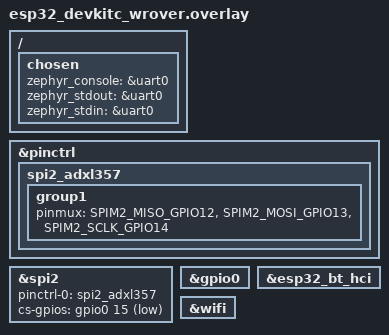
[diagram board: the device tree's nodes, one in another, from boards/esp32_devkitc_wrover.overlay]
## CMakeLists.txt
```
cmake_minimum_required(VERSION 3.20.0)
# Top-level CMakeLists.txt for the skeleton application.
#
# Copyright (c) 2017 Open Source Foundries Limited
#
# SPDX-License-Identifier: Apache-2.0
#
# This provides a basic application structure suitable for communication using
# mcumgr.  It can be used as a starting point for new applications.

# Standard Zephyr application boilerplate.
find_package(Zephyr REQUIRED HINTS $ENV{ZEPHYR_BASE})
project(smp)

target_sources(app PRIVATE src/main.c)
target_sources_ifdef(CONFIG_GPIO app PRIVATE src/sensor.c)
target_sources_ifdef(CONFIG_MCUMGR_TRANSPORT_UDP app PRIVATE src/wifi.c)
target_sources_ifdef(CONFIG_MCUMGR_TRANSPORT_BT app PRIVATE src/bluetooth.c)
target_sources_ifdef(CONFIG_SHELL app PRIVATE src/shell.c)
```

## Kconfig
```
mainmenu "Zephyr"
source "Kconfig.zephyr"
menu "Shell Configuration"
config MCUMGR_CMD_SHELL_MGMT
    bool "Enable mcumgr handlers for shell management"
    select SHELL_BACKEND_DUMMY
    depends on SHELL && MCUMGR
    help
      Enables mcumgr handlers for shell management. The handler will utilize
      the dummy backend to execute shell commands and capture the output to
      an internal memory buffer. This way, there is no interaction with
      physical interfaces outside of the scope of the user.
      It is possible to use additional shell backends in coordination
      with this handler and they will not interfere.

endmenu
```

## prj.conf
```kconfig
# Enable MCUmgr and dependencies.
CONFIG_NET_BUF=y
CONFIG_ZCBOR=y
CONFIG_CRC=y
CONFIG_MCUMGR=y
CONFIG_STREAM_FLASH=y
CONFIG_FLASH_MAP=y
CONFIG_BOOT_BANNER=y
CONFIG_STDOUT_CONSOLE=y

# Some command handlers require a large stack.
CONFIG_ESPTOOLPY_FLASHSIZE_8MB=y
CONFIG_MAIN_STACK_SIZE=8192
CONFIG_SYSTEM_WORKQUEUE_STACK_SIZE=8192

# Ensure an MCUboot-compatible binary is generated.
# ./esptool.py --chip esp32 --port /dev/ttyUSB0 write_flash 0x1000 build/bootloader/zephyr/zephyr.bin for use mcuboot
CONFIG_BOOTLOADER_MCUBOOT=n

# Enable flash operations.
CONFIG_FLASH=y

# Enable statistics and statistic names.
CONFIG_STATS=y
CONFIG_STATS_NAMES=y

# For debugging purposes.
# CONFIG_THREAD_ANALYZER=y
# CONFIG_THREAD_NAME=y /bu
# CONFIG_ASSERT=y
# CONFIG_STACK_SENTINEL=y /bu
# CONFIG_DEBUG_OPTIMIZATIONS=y

# Enable most core commands.
# CONFIG_BOOTLOADER_MCUBOOT
CONFIG_IMG_MANAGER=n
CONFIG_MCUMGR_GRP_IMG=n
CONFIG_MCUMGR_GRP_OS=y
CONFIG_MCUMGR_GRP_STAT=y

# Required by the `taskstat` command.
CONFIG_THREAD_MONITOR=y

# Enable OS management for echo and taskstat commands.
CONFIG_MCUMGR_GRP_OS_ECHO=y
CONFIG_MCUMGR_GRP_OS_TASKSTAT=y

# Enable logging
CONFIG_LOG=n
CONFIG_MCUBOOT_UTIL_LOG_LEVEL_WRN=n
# Disable debug logging
# CONFIG_LOG_MAX_LEVEL=3

# For writing
CONFIG_CONSOLE=y
CONFIG_UART_CONSOLE=y
CONFIG_PRINTK=y
```

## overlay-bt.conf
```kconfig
CONFIG_BT=y
CONFIG_BT_HCI=y
CONFIG_BT_DEVICE_NAME="ESP32 Zephyr SMP"
CONFIG_BT_PERIPHERAL=y

# Allow for large Bluetooth data packets.
CONFIG_BT_L2CAP_TX_MTU=512
CONFIG_BT_BUF_ACL_RX_SIZE=512
CONFIG_BT_BUF_ACL_TX_SIZE=512
CONFIG_SHELL_CMD_BUFF_SIZE=256
CONFIG_MCUMGR_TRANSPORT_NETBUF_SIZE=1024

CONFIG_BT_GATT_DYNAMIC_DB=y
# Enable the long workqueue for Bluetooth.
CONFIG_BT_LONG_WQ=y

# Disable pairing/encryption
CONFIG_BT_PRIVACY=n
# CONFIG_BT_SMP=n
CONFIG_BT_BONDABLE=n

# MCUMGR shell transport.
CONFIG_BASE64=y
CONFIG_SHELL=y
CONFIG_CRC=y
CONFIG_SHELL_BACKEND_SERIAL=y
CONFIG_SHELL_BACKEND_DUMMY=y
CONFIG_MCUMGR_GRP_SHELL=y
CONFIG_MCUMGR_TRANSPORT_SHELL=n

# Enable the LittleFS file system.
CONFIG_FILE_SYSTEM=y
CONFIG_FILE_SYSTEM_LITTLEFS=y

# Enable file system commands
CONFIG_MCUMGR_GRP_FS=y

# Enable the Bluetooth mcumgr transport (unauthenticated).
CONFIG_MCUMGR_TRANSPORT_BT=y
CONFIG_MCUMGR_LOG_LEVEL_DBG=y
CONFIG_MCUMGR_TRANSPORT_BT_CONN_PARAM_CONTROL=y

# Config size for Bluetooth stacks and workqueues.
CONFIG_SHELL_BACKEND_DUMMY_BUF_SIZE=2048
CONFIG_BT_RX_STACK_SIZE=4096
CONFIG_MCUMGR_TRANSPORT_WORKQUEUE_STACK_SIZE=4096
CONFIG_SHELL_STACK_SIZE=4096

# If you want to change BT_HCI_TX_STACK_SIZE you should do it from the menuconfig.
# CONFIG_BT_HCI_TX_STACK_SIZE=4096
# CONFIG_BT_LONG_WQ_STACK_SIZE=4096
# CONFIG_BT_HCI_TX_STACK_SIZE=4096
```

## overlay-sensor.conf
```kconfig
CONFIG_SPI=y
CONFIG_GPIO=y
CONFIG_PINCTRL=y
CONFIG_SPI_EXTENDED_MODES=y
CONFIG_NEWLIB_LIBC=n
CONFIG_MINIMAL_LIBC=y
CONFIG_COMMON_LIBC_MALLOC_ARENA_SIZE=4096
CONFIG_STDOUT_CONSOLE=n
CONFIG_CBPRINTF_FP_SUPPORT=y
CONFIG_SHELL_LOG_BACKEND=y
CONFIG_LOG_MODE_IMMEDIATE=y
```

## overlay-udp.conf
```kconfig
# MCUmgr UDP
CONFIG_MCUMGR_TRANSPORT_UDP=y
CONFIG_MCUMGR_TRANSPORT_UDP_IPV4=y
CONFIG_MCUMGR_TRANSPORT_UDP_PORT=1337

# MCUMGR shell transport.
CONFIG_BASE64=y
CONFIG_SHELL=y
CONFIG_CRC=y
CONFIG_SHELL_BACKEND_SERIAL=y
CONFIG_SHELL_BACKEND_DUMMY=y
CONFIG_MCUMGR_GRP_SHELL=y
CONFIG_MCUMGR_TRANSPORT_SHELL=n


# Debug logs to catch socket()/bind() failures
CONFIG_LOG=n
CONFIG_NET_LOG=n
CONFIG_THREAD_ANALYZER=n
CONFIG_WIFI_LOG_LEVEL_INF=n
CONFIG_LOG_BACKEND_UART=n
CONFIG_LOG_MODE_IMMEDIATE=n
# CONFIG_WIFI_LOG_LEVEL_DBG=y

# Networking core
CONFIG_NETWORKING=y
CONFIG_NET_SHELL=y
CONFIG_NET_IPV4=y
CONFIG_NET_MGMT=y
CONFIG_NET_UDP=y
CONFIG_NET_SOCKETS=y
CONFIG_NET_CONNECTION_MANAGER=y
CONFIG_NET_CONFIG_SETTINGS=y
CONFIG_NET_CONFIG_AUTO_INIT=n
CONFIG_NET_DHCPV4=y


# ESP32 Wi‑Fi driver + required L2 shim
CONFIG_NEWLIB_LIBC=y
CONFIG_WIFI=y
CONFIG_WIFI_ESP32=y
CONFIG_NET_L2_WIFI_MGMT=y
CONFIG_NET_L2_WIFI_SHELL=y
CONFIG_NET_L2_ETHERNET=y

CONFIG_NET_MGMT_EVENT=y
CONFIG_NET_MGMT_EVENT_INFO=y

# Shell capture buffers (optional but helpful)
CONFIG_SHELL_BACKEND_DUMMY_BUF_SIZE=2048
CONFIG_MCUMGR_TRANSPORT_NETBUF_SIZE=2048


CONFIG_NET_PKT_RX_COUNT=10
CONFIG_NET_PKT_TX_COUNT=10

CONFIG_NET_BUF_RX_COUNT=20
CONFIG_NET_BUF_TX_COUNT=20

CONFIG_NET_MAX_CONTEXTS=10

CONFIG_POSIX_MAX_FDS=32
CONFIG_NET_SOCKETS_POLL_MAX=8

# Safer stacks for net paths
CONFIG_NET_RX_STACK_SIZE=12288
CONFIG_NET_TX_STACK_SIZE=8192
CONFIG_MCUMGR_TRANSPORT_UDP_STACK_SIZE=8192
CONFIG_MCUMGR_TRANSPORT_WORKQUEUE_STACK_SIZE=8192

# Remove until working
# CONFIG_TEST_RANDOM_GENERATOR=y
# CONFIG_NET_CONFIG_MY_IPV4_ADDR="192.168.88.244"
```

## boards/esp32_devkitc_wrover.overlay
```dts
#include <zephyr/dt-bindings/pinctrl/esp32-pinctrl.h>

/ {
    chosen {
        zephyr_console = &uart0;
        zephyr_stdout  = &uart0;
        zephyr_stdin   = &uart0;
    };
};

&pinctrl {
    spi2_adxl357: spi2_adxl357 {
        group1 {
            pinmux = <SPIM2_MISO_GPIO12>,    // MISO → GPIO12
                     <SPIM2_MOSI_GPIO13>,    // MOSI → GPIO13
                     <SPIM2_SCLK_GPIO14>;    // SCLK → GPIO14
        };
    };
};

&spi2 {
    status = "okay";
    pinctrl-0 = <&spi2_adxl357>;
    pinctrl-names = "default";
    cs-gpios = <&gpio0 15 GPIO_ACTIVE_LOW>;
};

&gpio0 {
    status = "okay";
};

&esp32_bt_hci {
    status = "okay";
};

&wifi {
	status = "okay";
};
```

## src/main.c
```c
#include <zephyr/kernel.h>
#include <zephyr/stats/stats.h>
#include <zephyr/usb/usb_device.h>
#include <zephyr/debug/thread_analyzer.h>

#ifdef CONFIG_MCUMGR_GRP_FS
#include <zephyr/device.h>
#include <zephyr/fs/fs.h>
#include <zephyr/fs/littlefs.h>
#endif
#ifdef CONFIG_MCUMGR_GRP_STAT
#include <zephyr/mgmt/mcumgr/grp/stat_mgmt/stat_mgmt.h>
#endif

#ifdef CONFIG_MCUMGR_TRANSPORT_SHELL
#include <zephyr/mgmt/mcumgr/transport/smp_shell.h>
#endif

#define LOG_LEVEL LOG_LEVEL_DBG
#include <zephyr/logging/log.h>
LOG_MODULE_REGISTER(smp_sample);

#include "common.h"

#define STORAGE_PARTITION_LABEL	storage_partition
#define STORAGE_PARTITION_ID	FIXED_PARTITION_ID(STORAGE_PARTITION_LABEL)

/* Define an example stats group; approximates seconds since boot. */
STATS_SECT_START(smp_svr_stats)
STATS_SECT_ENTRY(ticks)
STATS_SECT_END;

/* Assign a name to the `ticks` stat. */
STATS_NAME_START(smp_svr_stats)
STATS_NAME(smp_svr_stats, ticks)
STATS_NAME_END(smp_svr_stats);

/* Define an instance of the stats group. */
STATS_SECT_DECL(smp_svr_stats) smp_svr_stats;

#ifdef CONFIG_MCUMGR_GRP_FS
FS_LITTLEFS_DECLARE_DEFAULT_CONFIG(cstorage);
static struct fs_mount_t littlefs_mnt = {
	.type = FS_LITTLEFS,
	.fs_data = &cstorage,
	.storage_dev = (void *)STORAGE_PARTITION_ID,
	.mnt_point = "/lfs1"
};
#endif

void check_threads(void) {
    thread_analyzer_print(0);
}

int main(void)
{
	int rc = STATS_INIT_AND_REG(smp_svr_stats, STATS_SIZE_32, "smp_svr_stats");

	if (rc < 0) {
		//LOG_ERR("Error initializing stats system [%d]", rc);
	}

	/* Register the built-in mcumgr command handlers. */
#ifdef CONFIG_MCUMGR_GRP_FS
	rc = fs_mount(&littlefs_mnt);
	if (rc < 0) {
		//LOG_ERR("Error mounting littlefs [%d]", rc);
	}
#endif

#ifdef CONFIG_MCUMGR_TRANSPORT_BT
	start_smp_bluetooth_adverts();
#endif

#ifdef CONFIG_MCUMGR_TRANSPORT_UDP
    start_smp_udp(); // prints IP or waits hint; UDP transport is auto-enabled by Kconfig
#endif

#ifdef CONFIG_MCUMGR_TRANSPORT_SHELL
	/* Initialize the shell transport. */
	rc = smp_shell_init();
	if (rc < 0) {
		//LOG_ERR("Error initializing shell transport [%d]", rc);
	}
#endif

//check_threads();
	while (1) {
		k_sleep(K_MSEC(1000));
		STATS_INC(smp_svr_stats, ticks);
	}
	return 0;
}
```

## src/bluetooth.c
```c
#include <zephyr/bluetooth/bluetooth.h>
#include <zephyr/bluetooth/conn.h>
#include <zephyr/bluetooth/gatt.h>
#include <zephyr/bluetooth/hci.h>
#include <zephyr/mgmt/mcumgr/transport/smp_bt.h>

#define LOG_LEVEL LOG_LEVEL_DBG
#include <zephyr/logging/log.h>
LOG_MODULE_REGISTER(smp_bt_sample);

static struct k_work advertise_work;

static const struct bt_data ad[] = {
	BT_DATA_BYTES(BT_DATA_FLAGS, (BT_LE_AD_GENERAL | BT_LE_AD_NO_BREDR)),
	BT_DATA_BYTES(BT_DATA_UUID128_ALL, SMP_BT_SVC_UUID_VAL),
};

static const struct bt_data sd[] = {
	BT_DATA(BT_DATA_NAME_COMPLETE, CONFIG_BT_DEVICE_NAME, sizeof(CONFIG_BT_DEVICE_NAME) - 1),
};

static void advertise(struct k_work *work)
{
	int rc;

	rc = bt_le_adv_start(BT_LE_ADV_CONN_FAST_1, ad, ARRAY_SIZE(ad), sd, ARRAY_SIZE(sd));
	if (rc) {
		//LOG_ERR("Advertising failed to start (rc %d)", rc);
		return;
	}

	//LOG_INF("Advertising successfully started");
}

static void connected(struct bt_conn *conn, uint8_t err)
{
	if (err) {
		//LOG_ERR("Connection failed, err 0x%02x %s", err, bt_hci_err_to_str(err));
		k_work_submit(&advertise_work);
	} else {
		////LOG_INF("Connected");
	}
}

static void disconnected(struct bt_conn *conn, uint8_t reason)
{
	//LOG_INF("Disconnected, reason 0x%02x %s", reason, bt_hci_err_to_str(reason));
}

static void on_conn_recycled(void)
{
	k_work_submit(&advertise_work);
}

BT_CONN_CB_DEFINE(conn_callbacks) = {
	.connected = connected,
	.disconnected = disconnected,
	.recycled = on_conn_recycled,
};

static void bt_ready(int err)
{
	if (err != 0) {
		//LOG_ERR("Bluetooth failed to initialise: %d", err);
	} else {
		k_work_submit(&advertise_work);
	}
}

void start_smp_bluetooth_adverts(void)
{
	int rc;

	k_work_init(&advertise_work, advertise);
	rc = bt_enable(bt_ready);

	if (rc != 0) {
		//LOG_ERR("Bluetooth enable failed: %d", rc);
	}
}
```

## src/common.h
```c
#ifndef COMMON_H
#define COMMON_H

#include <zephyr/shell/shell.h>

void start_smp_bluetooth_adverts(void);
int start_smp_udp(void);
void start_smp_sensor(const struct shell *shell);
void stop_smp_sensor(void);
int sensor_read_once(char *buf, size_t len);

#endif
```

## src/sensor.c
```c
#include <zephyr/device.h>
#include <zephyr/drivers/spi.h>
#include <zephyr/drivers/gpio.h>
#include <zephyr/kernel.h>
#include <zephyr/sys/printk.h>
#include <zephyr/shell/shell.h>
#include <zephyr/shell/shell_uart.h>
#include <zephyr/sys/atomic.h>
#include <zephyr/devicetree.h>
#include <zephyr/version.h>
#include <errno.h>
#include <stdlib.h>
#include <stdio.h>

#define ADXL357_REG_DEVID_AD 0x00
#define ADXL357_REG_DEVID_MST 0x01
#define ADXL357_REG_PARTID 0x02
#define ADXL357_REG_REVID 0x03
#define ADXL357_REG_STATUS 0x04
#define ADXL357_REG_FIFO_ENTRIES 0x05
#define ADXL357_REG_TEMP2 0x06
#define ADXL357_REG_TEMP1 0x07
#define ADXL357_REG_XDATA3 0x08
#define ADXL357_REG_XDATA2 0x09
#define ADXL357_REG_XDATA1 0x0A
#define ADXL357_REG_YDATA3 0x0B
#define ADXL357_REG_YDATA2 0x0C
#define ADXL357_REG_YDATA1 0x0D
#define ADXL357_REG_ZDATA3 0x0E
#define ADXL357_REG_ZDATA2 0x0F
#define ADXL357_REG_ZDATA1 0x10
#define ADXL357_REG_FIFO_DATA 0x11
#define ADXL357_REG_ACT_EN 0x24
#define ADXL357_REG_ACT_THRESH_H 0x25
#define ADXL357_REG_ACT_THRESH_L 0x26
#define ADXL357_REG_ACT_COUNT 0x27
#define ADXL357_REG_POWER_CTL 0x2D
#define ADXL357_REG_RANGE 0x2C

#define ADXL357_READ_CMD 0x01
#define ADXL357_WRITE_CMD 0x00

K_MUTEX_DEFINE(sensor_mutex);
static bool adxl_inited = false;

static const struct device *spi_dev;
static struct spi_config spi_cfg;
static const struct gpio_dt_spec cs_gpio = GPIO_DT_SPEC_GET_BY_IDX(DT_NODELABEL(spi2), cs_gpios, 0);
static struct spi_cs_control spi_cs = {
    .gpio = GPIO_DT_SPEC_GET_BY_IDX(DT_NODELABEL(spi2), cs_gpios, 0),
    .delay = 10,
};
float temp_c = 0.0f;

uint8_t adxl357_read_reg(uint8_t reg)
{
  uint8_t tx_buf[2] = {(reg << 1) | ADXL357_READ_CMD, 0x00};
  uint8_t rx_buf[2] = {0};

  struct spi_buf tx_spi_buf = {.buf = tx_buf, .len = 2};
  struct spi_buf rx_spi_buf = {.buf = rx_buf, .len = 2};

  struct spi_buf_set tx_spi_buf_set = {.buffers = &tx_spi_buf, .count = 1};
  struct spi_buf_set rx_spi_buf_set = {.buffers = &rx_spi_buf, .count = 1};

  int ret = spi_transceive(spi_dev, &spi_cfg, &tx_spi_buf_set, &rx_spi_buf_set);
  if (ret < 0)
  {
    printk("SPI transceive failed: %d\n", ret);
    return 0;
  }
  /*
  // Add debug print
  printk("Read reg 0x%02X: tx[0]=0x%02X, tx[1]=0x%02X, rx[0]=0x%02X, rx[1]=0x%02X\n",
         reg, tx_buf[0], tx_buf[1], rx_buf[0], rx_buf[1]);
*/
  return rx_buf[1];
}

void adxl357_write_reg(uint8_t reg, uint8_t value)
{
  uint8_t tx_buf[2] = {(reg << 1) | ADXL357_WRITE_CMD, value};
  uint8_t rx_buf[2] = {0}; // Add receive buffer

  struct spi_buf tx_spi_buf = {.buf = tx_buf, .len = 2};
  struct spi_buf rx_spi_buf = {.buf = rx_buf, .len = 2}; // Add this

  struct spi_buf_set tx_spi_buf_set = {.buffers = &tx_spi_buf, .count = 1};
  struct spi_buf_set rx_spi_buf_set = {.buffers = &rx_spi_buf, .count = 1}; // Add this

  // Use spi_transceive instead of spi_write
  int ret = spi_transceive(spi_dev, &spi_cfg, &tx_spi_buf_set, &rx_spi_buf_set);
  if (ret < 0)
  {
    // printk("SPI write failed: %d\n", ret);
  }

  // Add debug print
  // printk("Write reg 0x%02X: tx[0]=0x%02X, tx[1]=0x%02X, value=0x%02X, ret=%d\n",reg, tx_buf[0], tx_buf[1], value, ret);
}

int32_t adxl357_read_axis(uint8_t reg_high)
{
  uint8_t msb = adxl357_read_reg(reg_high);     // MSB
  uint8_t mid = adxl357_read_reg(reg_high + 1); // MID
  uint8_t lsb = adxl357_read_reg(reg_high + 2); // LSB

  // Combine 20-bit data (sign extend)
  int32_t result = ((msb << 16) | (mid << 8) | lsb) >> 4; // Discard lower 4 bits

  // Sign extend from 20-bit to 32-bit
  if (result & 0x80000)
  {
    result |= 0xFFF00000;
  }

  return result;
}

uint16_t adxl357_read_temp_raw(void)
{
  uint8_t temp2 = adxl357_read_reg(ADXL357_REG_TEMP2) & 0x0F; // 4 MSB
  uint8_t temp1 = adxl357_read_reg(ADXL357_REG_TEMP1);        // 8 LSB
  return ((temp2 << 8) | temp1);                              // 12-bit value
}

float adxl357_temp_celsius(void)
{
  uint16_t temp_raw = adxl357_read_temp_raw();
  // Nominal intercept: 1885 LSB at 25°C, slope: -9.05 LSB/°C
  return (1885.0f - (float)temp_raw) / 9.05f + 25.0f;
}

/* Forward declaration of thread entry */
static void sensor_thread(void *p1, void *p2, void *p3);

static struct k_thread sensor_thread_data;
K_THREAD_STACK_DEFINE(sensor_thread_stack, 4096);
static atomic_t sensor_thread_started = ATOMIC_INIT(0);
static atomic_t sensor_thread_stop = ATOMIC_INIT(0);

/* Start function called from shell command */
void start_smp_sensor(const struct shell *shell)
{
  if (atomic_cas(&sensor_thread_started, 0, 1))
  {
    atomic_set(&sensor_thread_stop, 0);
    /* First time: spawn */
    k_thread_create(&sensor_thread_data, sensor_thread_stack,
                    K_THREAD_STACK_SIZEOF(sensor_thread_stack),
                    sensor_thread, (void *)shell, NULL, NULL,
                    K_PRIO_PREEMPT(12), 0, K_NO_WAIT);
    k_thread_name_set(&sensor_thread_data, "adxl357");
    printk("sensor thread created (prio %d, stack %u)\n",
           k_thread_priority_get(k_current_get()),
           (unsigned)K_THREAD_STACK_SIZEOF(sensor_thread_stack));
  }
  else
  {
    printk("sensor thread already running\n");
  }
}

void stop_smp_sensor(void)
{
  if (!atomic_get(&sensor_thread_started))
  {
    printk("Sensor thread not running\n");
    return;
  }
  atomic_set(&sensor_thread_stop, 1);

  /* Wait (up to 500 ms) for graceful exit, then abort */
  for (int i = 0; i < 50; i++)
  {
    if (!atomic_get(&sensor_thread_started))
    {
      printk("Sensor thread stopped\n");
      return;
    }
    k_sleep(K_MSEC(10));
  }
  printk("Sensor thread aborting\n");
  printk("\033[2J\033[H");
  k_thread_abort(&sensor_thread_data);
  atomic_set(&sensor_thread_started, 0);
}

// Check
static int adxl357_init_once(void)
{
  if (adxl_inited)
  {
    return 0;
  }

  spi_dev = DEVICE_DT_GET(DT_NODELABEL(spi2));
  if (!device_is_ready(spi_dev))
  {
    printk("SPI device not ready\n");
    return -ENODEV;
  }
  if (!gpio_is_ready_dt(&cs_gpio))
  {
    printk("CS GPIO not ready\n");
    return -ENODEV;
  }
  int ret = gpio_pin_configure_dt(&cs_gpio, GPIO_OUTPUT_INACTIVE);
  if (ret < 0)
  {
    printk("Failed CS GPIO cfg: %d\n", ret);
    return ret;
  }

  spi_cfg.operation = SPI_WORD_SET(8) | SPI_TRANSFER_MSB;
  spi_cfg.frequency = 1000000;
  spi_cfg.slave = 0;
  spi_cfg.cs = spi_cs;

  k_sleep(K_MSEC(100));

  uint8_t dev_id = adxl357_read_reg(ADXL357_REG_DEVID_AD);
  uint8_t part_id = adxl357_read_reg(ADXL357_REG_PARTID);
  if (dev_id != 0xAD || part_id != 0xED)
  {
    printk("Device ID mismatch (got 0x%02X 0x%02X)\n", dev_id, part_id);
    return -EIO;
  }

  adxl357_write_reg(ADXL357_REG_POWER_CTL, 0x01);
  k_sleep(K_MSEC(50));
  adxl357_write_reg(ADXL357_REG_POWER_CTL, 0x00);
  k_sleep(K_MSEC(50));
  adxl357_write_reg(ADXL357_REG_RANGE, 0x01);

  adxl_inited = true;
  return 0;
}

// 20-bit two's complement spans ±2^19 counts.
static inline float adxl357_counts_per_g(void)
{
  uint8_t r = adxl357_read_reg(ADXL357_REG_RANGE) & 0x03;
  int fs_g; // full-scale in g
  switch (r)
  {
  case 0x01:
    fs_g = 10;
    break; // ±10 g
  case 0x02:
    fs_g = 20;
    break; // ±20 g
  case 0x03:
    fs_g = 40;
    break; // ±40 g
  default:
    fs_g = 10;
    break; // fallback
  }
  return (float)(1 << 19) / (float)fs_g; // 524288 / FS[g]
}

static inline float adxl357_to_g(int32_t raw20)
{
  return (float)raw20 / adxl357_counts_per_g();
}

static inline float g_to_ms2(float g)
{
  return g * 9.80665f;
}

// Read regularly (UART)
static void sensor_thread(void *p1, void *p2, void *p3)
{
  const struct shell *shell = (const struct shell *)p1;
  ARG_UNUSED(p2);
  ARG_UNUSED(p3);
  /* Fallback if no shell pointer */
  if (!shell)
  {
    shell = shell_backend_uart_get_ptr();
    printk("Sensor shell not set, using UART shell\n");
  }

  for (int i = 0; i < 3; i++)
  {
    printk("sensor init phase %d\n", i);
    k_sleep(K_MSEC(50));
  }

  printk("Starting ADXL357 SPI application\n");

  spi_dev = DEVICE_DT_GET(DT_NODELABEL(spi2));
  if (!device_is_ready(spi_dev))
  {
    printk("SPI device not ready\n");
    goto done;
  }
  if (!gpio_is_ready_dt(&cs_gpio))
  {
    printk("CS GPIO not ready\n");
    goto done;
  }
  int ret = gpio_pin_configure_dt(&cs_gpio, GPIO_OUTPUT_INACTIVE);
  if (ret < 0)
  {
    printk("Failed CS GPIO cfg: %d\n", ret);
    goto done;
  }

  spi_cfg.operation = SPI_WORD_SET(8) | SPI_TRANSFER_MSB;
  spi_cfg.frequency = 1000000;
  spi_cfg.slave = 0;
  spi_cfg.cs = spi_cs;

  k_sleep(K_MSEC(100));
  ret = adxl357_init_once();
  if (ret != 0)
  {
    printk("Failed init: %d\n", ret);
    goto done;
  }

  while (!atomic_get(&sensor_thread_stop))
  {
    uint8_t stat = adxl357_read_reg(ADXL357_REG_STATUS);
    if (stat & 0x01)
    {
      float t = adxl357_temp_celsius();
      int32_t x = adxl357_read_axis(ADXL357_REG_XDATA3);
      int32_t y = adxl357_read_axis(ADXL357_REG_YDATA3);
      int32_t z = adxl357_read_axis(ADXL357_REG_ZDATA3);

      float gx = adxl357_to_g(x);
      float gy = adxl357_to_g(y);
      float gz = adxl357_to_g(z);
      t = adxl357_temp_celsius();

      printk("X:%.3f m/s^2 "
             "Y:%.3f m/s^2 "
             "Z:%.3f m/s^2 T:%.2f C\n",
             (double)g_to_ms2(gx),
             (double)g_to_ms2(gy),
             (double)g_to_ms2(gz), (double)t);
    }
    else
    {
      printk("STATUS 0x%02X\n", stat);
    }
    k_sleep(K_MSEC(200));
  }
done:
  atomic_set(&sensor_thread_started, 0);
  printk("Sensor thread exiting\n");
  shell = NULL;
}

// Public one-shot read (to be called from shell)
int sensor_read_once(char *buf, size_t len)
{
  if (!buf || len == 0)
    return -EINVAL;

  int rc = k_mutex_lock(&sensor_mutex, K_MSEC(200));
  if (rc != 0)
    return -EBUSY;

  rc = adxl357_init_once();

  if (rc != 0)
  {
    k_mutex_unlock(&sensor_mutex);
    snprintf(buf, len, "init failed (%d)", rc);
    return rc;
  }

  uint8_t stat = adxl357_read_reg(ADXL357_REG_STATUS);

  if (stat & 0x01)
  {
    float t = adxl357_temp_celsius();
    int32_t x = adxl357_read_axis(ADXL357_REG_XDATA3);
    int32_t y = adxl357_read_axis(ADXL357_REG_YDATA3);
    int32_t z = adxl357_read_axis(ADXL357_REG_ZDATA3);
    float gx = adxl357_to_g(x), gy = adxl357_to_g(y), gz = adxl357_to_g(z);

    snprintf(buf, len, "X:%.3f m/s^2 "
                       "Y:%.3f m/s^2 "
                       "Z:%.3f m/s^2 T:%.2f C\n",
                       (double)g_to_ms2(gx),
                       (double)g_to_ms2(gy),
                       (double)g_to_ms2(gz), (double)t);
    rc = 0;
  }
  else
  {
    snprintf(buf, len, "STATUS 0x%02X", stat);
    rc = -EAGAIN;
  }

  k_mutex_unlock(&sensor_mutex);
  return rc;
}

// --- IGNORE ---
/*
printk("X:%ld (%.3fg, %.1fmg, %.3fm/s^2) "
          "Y:%ld (%.3fg, %.1fmg, %.3fm/s^2) "
          "Z:%ld (%.3fg, %.1fmg, %.3fm/s^2) T:%.2fC\n",
          (long)x, (double)gx, (double)(gx * 1000.0f), (double)g_to_ms2(gx),
          (long)y, (double)gy, (double)(gy * 1000.0f), (double)g_to_ms2(gy),
          (long)z, (double)gz, (double)(gz * 1000.0f), (double)g_to_ms2(gz), (double)t);
*/
```

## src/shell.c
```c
#include <zephyr/kernel.h>
#include <zephyr/shell/shell.h>
#include <zephyr/device.h>
#include <zephyr/devicetree.h>
#include <zephyr/sys/printk.h>
#include <zephyr/version.h>
#include "common.h"


static int cmd_sensor(const struct shell *shell, size_t argc, char **argv)
{
    ARG_UNUSED(argc); ARG_UNUSED(argv);
    shell_print(shell, "Starting sensor thread on UART...");
    start_smp_sensor(shell);
    return 0;
}

static int cmd_sensor_once(const struct shell *shell, size_t argc, char **argv)
{
    ARG_UNUSED(argc); ARG_UNUSED(argv);
    char buf[64];
    int rc = sensor_read_once(buf, sizeof(buf));
    if (rc == 0) {
        shell_print(shell, "%s", buf);
    } else {
        // still print what we have (e.g., STATUS or error text)
        shell_print(shell, "%s (rc=%d)", buf, rc);
    }
    return 0;
}

static int cmd_exit_sensor(const struct shell *shell, size_t argc, char **argv)
{
    ARG_UNUSED(argc); ARG_UNUSED(argv);
    shell_print(shell, "Stopping sensor thread (exit)...");
    stop_smp_sensor();
    return 0;
}

static int cmd_hello(const struct shell *shell, size_t argc, char **argv) {
    ARG_UNUSED(argc); ARG_UNUSED(argv);
    shell_print(shell, "Hello, Zephyr Shell!");
    return 0;
}
static int cmd_listall(const struct shell *shell, size_t argc, char **argv) {
    ARG_UNUSED(argc); ARG_UNUSED(argv);
    shell_print(shell, "\n=== Device Information ===");
    // System Information
    shell_print(shell, "\n--- System Info ---");
    shell_print(shell, "Board: %s", CONFIG_BOARD);
    shell_print(shell, "SoC: %s", CONFIG_SOC);
    shell_print(shell, "Zephyr Version: %s", KERNEL_VERSION_STRING);
    shell_print(shell, "Build Time: %s %s", __DATE__, __TIME__);
    // Runtime Information
    shell_print(shell, "\n--- Runtime Info ---");
    shell_print(shell, "Uptime: %llu ms", (unsigned long long)k_uptime_get());
    shell_print(shell, "CPU Frequency: %d Hz", sys_clock_hw_cycles_per_sec());

#ifdef CONFIG_NETWORKING
    shell_print(shell, "\n--- Network Info ---");
    shell_print(shell, "Networking: Enabled");

#ifdef CONFIG_MCUMGR_TRANSPORT_UDP
    shell_print(shell, "UDP Transport: Enabled (Port 1337)");
#endif
#else
    shell_print(shell, "\n--- Network Info ---");
    shell_print(shell, "Networking: Disabled");
#endif

    // MCUmgr Information
    shell_print(shell, "\n--- MCUmgr Info ---");
#ifdef CONFIG_MCUMGR_TRANSPORT_UART
    shell_print(shell, "UART Transport: Enabled");
#endif

#ifdef CONFIG_MCUMGR_TRANSPORT_BT
    shell_print(shell, "Bluetooth Transport: Enabled");
#endif

    // Hardware Information
    shell_print(shell, "--- Hardware Info ---");
    shell_print(shell, "Board: %s", CONFIG_BOARD);
    shell_print(shell, "=== End Device Info ===");

    return 0;
}


// Register shell commands
SHELL_CMD_REGISTER(hello, NULL, "Say hello", cmd_hello);
SHELL_CMD_REGISTER(listall, NULL, "List all device information", cmd_listall);
SHELL_CMD_REGISTER(sensor, NULL, "Start sensor task", cmd_sensor);
SHELL_CMD_REGISTER(sensoronce, NULL, "Read sensor once and print immediately", cmd_sensor_once);
SHELL_CMD_REGISTER(exitsensor, NULL, "Stop sensor thread", cmd_exit_sensor);
```

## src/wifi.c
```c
#include <zephyr/kernel.h>
#include <zephyr/sys/printk.h>
#include <zephyr/shell/shell.h>
#include <zephyr/net/net_if.h>
#include <zephyr/net/net_ip.h>
#include <zephyr/net/net_mgmt.h>
#include <zephyr/net/net_event.h>
#include <zephyr/net/wifi_mgmt.h>
#include <string.h>
#include <errno.h>

static void print_udp_smp_addr(struct net_if *iface)
{
#ifdef CONFIG_MCUMGR_TRANSPORT_UDP
    if (!iface) {
        return;
    }

    struct net_if_config *cfg = net_if_get_config(iface);
    if (cfg && cfg->ip.ipv4) {
        struct net_if_addr_ipv4 *ua = &cfg->ip.ipv4->unicast[0];
        if (ua->ipv4.addr_state == NET_ADDR_TENTATIVE ||
            ua->ipv4.addr_state == NET_ADDR_PREFERRED) {
            char addr[NET_IPV4_ADDR_LEN];
            net_addr_ntop(AF_INET, &ua->ipv4.address.in_addr, addr, sizeof(addr));
            printk("UDP SMP: %s:%d\n", addr, CONFIG_MCUMGR_TRANSPORT_UDP_PORT);
        }
    }
#endif
}

static struct net_mgmt_event_callback ipv4_cb;
static bool cb_registered;

static void ipv4_event_handler(struct net_mgmt_event_callback *cb,
                               uint32_t mgmt_event, struct net_if *iface)
{
    ARG_UNUSED(cb);

    if (mgmt_event == NET_EVENT_IPV4_ADDR_ADD ||
        mgmt_event == NET_EVENT_IPV4_DHCP_BOUND) {
        print_udp_smp_addr(iface);
    }
}

// Called from main() to print where UDP SMP will listen
int start_smp_udp(void)
{
#ifdef CONFIG_MCUMGR_TRANSPORT_UDP
    struct net_if *iface = net_if_get_default();
    if (!iface) {
        printk("UDP SMP: no default net_if\n");
        return -ENODEV;
    }

    // Try to print immediately if IPv4 is already assigned
    struct net_if_config *cfg = net_if_get_config(iface);
    if (cfg && cfg->ip.ipv4) {
        struct net_if_addr_ipv4 *ua = &cfg->ip.ipv4->unicast[0];
        if (ua->ipv4.addr_state == NET_ADDR_TENTATIVE ||
            ua->ipv4.addr_state == NET_ADDR_PREFERRED) {
                print_udp_smp_addr(iface);
                return 0;
        }
    }

    // Otherwise wait for IPv4 via net mgmt events
    if (!cb_registered) {
        net_mgmt_init_event_callback(&ipv4_cb, ipv4_event_handler,
                                     NET_EVENT_IPV4_ADDR_ADD |
                                     NET_EVENT_IPV4_DHCP_BOUND);
        net_mgmt_add_event_callback(&ipv4_cb);
        cb_registered = true;
    }
    printk("UDP SMP: waiting for IPv4\n");
#else
    printk("UDP SMP transport not enabled\n");
#endif
    return 0;
}
```
